BO_ 96 CAR_OVERALL_SIGNALS2: 64 XXX
 SG_ CRC1 : 7|8@0+ (1,0) [0|255] "" XXX
 SG_ COUNTER1 : 59|4@0+ (1,0) [0|15] "" XXX
 SG_ CRC2 : 71|8@0+ (1,0) [0|255] "" XXX
 SG_ BRAKE_SIGNAL : 86|1@0+ (1,0) [0|1] "" XXX

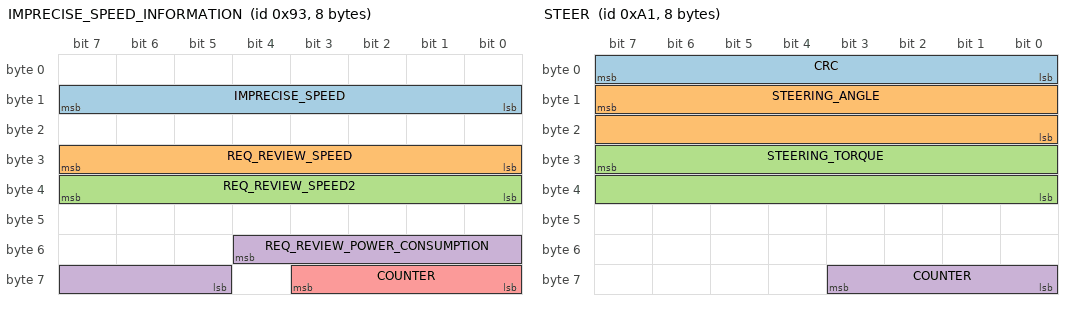
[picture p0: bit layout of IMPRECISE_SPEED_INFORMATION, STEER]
BO_ 147 IMPRECISE_SPEED_INFORMATION: 8 XXX
 SG_ IMPRECISE_SPEED : 15|8@0+ (3.5,0) [0|255] "kph" XXX
 SG_ REQ_REVIEW_SPEED : 31|8@0+ (0.430107526,0) [0|255] "Kph" XXX
 SG_ REQ_REVIEW_SPEED2 : 39|8@0+ (0.430107526,0) [0|255] "Kph" XXX
 SG_ REQ_REVIEW_POWER_CONSUMPTION : 52|8@0+ (1,0) [0|255] "" XXX
 SG_ COUNTER : 59|4@0+ (1,0) [0|15] "" XXX

BO_ 161 STEER: 8 XXX
 SG_ CRC : 7|8@0+ (1,0) [0|255] "" XXX
 SG_ STEERING_ANGLE : 15|16@0+ (0.05,0) [0|65535] "degs" XXX
 SG_ STEERING_TORQUE : 31|16@0+ (1,0) [0|65535] "??" XXX
 SG_ COUNTER : 59|4@0+ (1,0) [0|255] "" XXX

BO_ 259 SPEED: 64 XXX
 SG_ CRC : 199|8@0+ (1,0) [0|255] "" XXX
 SG_ UNDEFINED_ACCUMULATOR : 207|8@0+ (1,0) [0|255] "" XXX
 SG_ UNDEFINED_COUNTER : 215|8@0+ (1,0) [0|255] "" XXX
 SG_ ODD_GAS_POSITION : 231|8@0+ (1,0) [0|255] "" XXX
 SG_ SPEED : 239|8@0+ (1,0) [0|255] "Khp" XXX
 SG_ COUNTER2 : 251|4@0+ (1,0) [0|15] "" XXX

BO_ 288 BRAKE: 64 XXX
 SG_ CRC : 7|8@0+ (1,0) [0|255] "" XXX
 SG_ REVIEW_REQ_BRAKE_SIGNAL1 : 15|8@0+ (1,0) [0|255] "" XXX
 SG_ REQ_REVIEW_MOVING : 22|1@0+ (1,0) [0|1] "" XXX
 SG_ ODD_BRAKE_PRESSURE : 39|8@0+ (1,-27) [0|255] "" XXX
 SG_ REVIEW_REQ_BRAKE_SIGNAL2 : 47|8@0+ (1,0) [0|255] "" XXX
 SG_ COUNTER : 59|4@0+ (1,0) [0|15] "" XXX

BO_ 299 NEW_MSG_12b: 64 XXX
 SG_ REQ_REVIEW_CRC : 71|8@0+ (1,0) [0|255] "" XXX
 SG_ AP_UNDEFINED_SIGNAL2 : 73|2@0+ (1,0) [0|3] "" XXX
 SG_ REQ_REVIEW_COUNTER : 78|5@0+ (1,0) [0|31] "" XXX
 SG_ AP_UNDEFINED_SIGNAL : 87|6@0+ (1,0) [0|63] "" XXX
 SG_ AP_STEERING_UNDEFINED_SIGNAL1 : 102|10@0- (1,0) [0|2047] "" XXX
 SG_ AP_UNDEFINED_SIGNAL3 : 103|1@0+ (1,0) [0|1] "" XXX
 SG_ COUNTER : 123|4@0+ (1,0) [0|15] "" XXX
 SG_ CRC : 135|8@0+ (1,0) [0|255] "" XXX

BO_ 303 CAR_OVERALL_SIGNALS: 64 XXX
 SG_ CRC1 : 71|8@0+ (1,0) [0|255] "" XXX
 SG_ DRIVE_MODE_SIGNAL : 73|1@0+ (1,0) [0|1] "" XXX
 SG_ REQ_REVIEW_POWER_STATE3 : 113|1@0+ (1,0) [0|1] "" XXX
 SG_ COUNTER1 : 123|4@0+ (1,0) [0|15] "" XXX
 SG_ CRC2 : 135|8@0+ (1,0) [0|255] "" XXX
 SG_ DRIVER_MODE_SIGNAL2 : 161|1@0+ (1,0) [0|1] "" XXX
 SG_ DRIVE_MODE : 166|2@0+ (1,0) [0|1] "" XXX
 SG_ BRAKE_SIGNAL : 176|1@0+ (1,0) [0|1] "" XXX
 SG_ COUNTER2 : 187|4@0+ (1,0) [0|15] "" XXX

BO_ 412 LIGHTS: 16 XXX
 SG_ BRAKE_LIGHTS : 24|3@0+ (1,0) [0|7] "" XXX
 SG_ RIGHT_TURN_SIGNAL : 30|1@0+ (1,0) [0|1] "ON/OFF ACCORDINGLY LIGHT" XXX
 SG_ LEFT_TURN_SIGNAL : 31|1@0+ (1,0) [0|1] "ON/OFF ACCORDINGLY LIGHT" XXX

BO_ 639 NEW_MSG_27F: 16 XXX
 SG_ CRC : 7|8@0+ (1,0) [0|255] "" XXX
 SG_ REQ_REVIEW_ODOMETER : 23|16@0+ (1,0) [0|65535] "" XXX
 SG_ COUNTER : 59|4@0+ (1,0) [0|15] "" XXX

BO_ 649 DRIVE_MODE: 64 XXX
 SG_ DRIVE_MODE_ENABLED : 382|1@0+ (1,0) [0|1] "" XXX
 SG_ DRIVE_MODE_DISABLED : 383|1@0+ (1,0) [0|1] "" XXA

BO_ 714 BUTTONS: 8 XXX
 SG_ LOCK_DOORS_BUTTON : 16|1@0+ (1,0) [0|1] "" XXX

BO_ 793 CAR_STATE: 16 XXX
 SG_ REQ_REVIEW_CAR_STATE : 16|1@0+ (1,0) [0|1] "" XXX
 SG_ DOOR_REAR_RIGHT_OPEN : 19|1@0+ (1,0) [0|1] "" XXX
 SG_ DOOR_FRONT_RIGHT_OPEN : 20|1@0+ (1,0) [0|1] "" XXX
 SG_ DOOR_REAR_LEFT_OPEN : 21|1@0+ (1,0) [0|1] "" XXX
 SG_ DOOR_DRIVER_OPEN : 22|1@0+ (1,0) [0|1] "" XXX

BO_ 837 DOOR_LOCK_STATES: 16 XXX
 SG_ DOOR_LOCK_STATE : 13|1@0+ (1,0) [0|1] "" XXX
 SG_ DOOR_LOCK_STATE2 : 34|1@0+ (1,0) [0|1] "" XXX

BO_ 849 SEATBELT: 16 XXX
 SG_ CRC : 7|8@0+ (1,0) [0|255] "" XXX
 SG_ SEAT_BELT_DRIVER_STATE : 19|1@0+ (1,0) [0|1] "" XXX
 SG_ SEAT_BELT_DRIVER_STATE2 : 33|1@0+ (1,0) [0|1] "" XXX
 SG_ COUNTER : 59|4@0+ (1,0) [0|15] "" XXX

CM_ SG_ 96 BRAKE_SIGNAL "1 = BRAKE PRESSED";
CM_ SG_ 147 IMPRECISE_SPEED "lower precision, reverse is positive as well";
CM_ SG_ 161 STEERING_ANGLE "0 CENTER, NO LEFT / RIGHT SIGNAL";
CM_ SG_ 161 STEERING_TORQUE "Peak identified 3680, 0 = stopped";
CM_ SG_ 259 UNDEFINED_ACCUMULATOR "WHEN ELETRIC MODE = 0, PERHAPS COMBUSTION ENGINE";
CM_ SG_ 259 UNDEFINED_COUNTER "0 WHEN ELECTRIC, PERHAPS COMBUSTION ENGINE";
CM_ SG_ 259 ODD_GAS_POSITION "17 = 0, 253 = FULL, SOMETIMES 4";
CM_ SG_ 259 SPEED "PRECISE, KPH, DASHBOARD SPEED, BIT LOWER THAN GPS SPEED";
CM_ SG_ 288 REVIEW_REQ_BRAKE_SIGNAL1 "0 | 128 SIMILAR TO BRAKE SIGNAL BUT ADDITIONAL DELAY";
CM_ SG_ 288 REQ_REVIEW_MOVING "1 = CAR IS MOVING";
CM_ SG_ 288 ODD_BRAKE_PRESSURE "ODD BRAKE PRESSURE, NEGATIVE/OFFSET";
CM_ SG_ 288 REVIEW_REQ_BRAKE_SIGNAL2 "0 | 128 BRAKE PRESSED";
CM_ SG_ 299 REQ_REVIEW_COUNTER "COUNTER NOT STABLE";
CM_ SG_ 303 DRIVE_MODE_SIGNAL "D/R = 0 | N/P = 1";
CM_ SG_ 303 REQ_REVIEW_POWER_STATE3 "0 = OFF / 1 = ON";
CM_ SG_ 303 DRIVER_MODE_SIGNAL2 "D/R = 1 | N/P=0";
CM_ SG_ 303 DRIVE_MODE "0 = P | 1 = D | 2 = N | 3 = R (GOOD SIGNAL)";
CM_ SG_ 412 BRAKE_LIGHTS "POSSIBLE 3 DIFFERENT LIGHTS";
CM_ SG_ 412 LEFT_TURN_SIGNAL "ON/OFF ACCORDINGLY LIGHT";
CM_ BO_ 573 "APPEARS TO HAVE GOOD MOVING INFORMATION";
CM_ BO_ 649 "FRONT";
CM_ SG_ 649 DRIVE_MODE_ENABLED "DRIVE = 1 | OTHER MODES = 0";
CM_ SG_ 649 DRIVE_MODE_DISABLED "D = 0 | OTHER MODES = 0";
CM_ BO_ 696 "POSSIBLE RELATED TO ACC OR ENGINE";
CM_ SG_ 714 LOCK_DOORS_BUTTON "1 = PRESSED";
CM_ SG_ 793 REQ_REVIEW_CAR_STATE "1 = STOPPED | 0 = MOVING";
CM_ SG_ 837 DOOR_LOCK_STATE "0 = LOCKED / 1 = UNLOCKED";
CM_ SG_ 837 DOOR_LOCK_STATE2 "0 = LOCKED / 1 = UNLOCKED";
CM_ SG_ 849 SEAT_BELT_DRIVER_STATE "0 = Fastened / 1 = Released";
CM_ SG_ 849 SEAT_BELT_DRIVER_STATE2 "0 = Fastened / 1 = Released";
